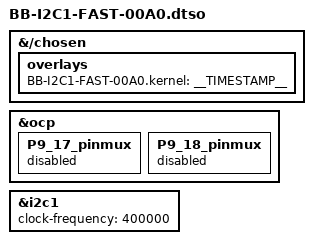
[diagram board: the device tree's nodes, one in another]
// SPDX-License-Identifier: GPL-2.0-only
/*
 * Copyright (C) 2013 CircuitCo
 */

/dts-v1/;
/plugin/;

#include <dt-bindings/pinctrl/am33xx.h>

/*
 * Helper to show loaded overlays under: /proc/device-tree/chosen/overlays/
 */
&{/chosen} {
	overlays {
		BB-I2C1-FAST-00A0.kernel = __TIMESTAMP__;
	};
};

/*
 * Free up the pins used by the cape from the pinmux helpers.
 */
&ocp {
	P9_17_pinmux { status = "disabled"; };	/* i2c1_scl */
	P9_18_pinmux { status = "disabled"; };	/* i2c1_sda */
};

&i2c1 {
	status = "okay";
	clock-frequency = <400000>;
};
